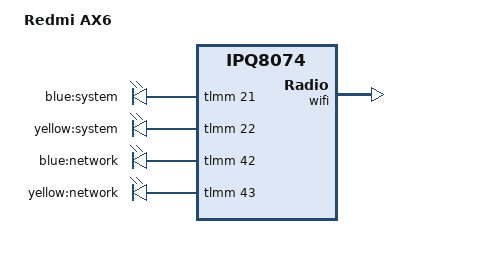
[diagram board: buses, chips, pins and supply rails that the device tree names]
// SPDX-License-Identifier: GPL-2.0-or-later OR MIT

/dts-v1/;

#include "ipq8071-xiaomi.dtsi"

/ {
	model = "Redmi AX6";
	compatible = "redmi,ax6", "qcom,ipq8074";

	leds {
		compatible = "gpio-leds";

		led_system_blue: system-blue {
			label = "blue:system";
			gpios = <&tlmm 21 GPIO_ACTIVE_HIGH>;
		};

		led_system_yellow: system-yellow {
			label = "yellow:system";
			gpios = <&tlmm 22 GPIO_ACTIVE_HIGH>;
		};

		network-blue {
			label = "blue:network";
			gpios = <&tlmm 42 GPIO_ACTIVE_HIGH>;
		};

		network-yellow {
			label = "yellow:network";
			gpios = <&tlmm 43 GPIO_ACTIVE_HIGH>;
		};
	};
};

/* AX6 can both have NAND of 256MiB or 128MiB.
 * To be on the safe side, assume 128MiB of NAND.
 */
&rootfs {
	reg = <0x02dc0000 0x05220000>;
};

&wifi {
	status = "okay";
	qcom,ath11k-fw-memory-mode = <1>;
	qcom,ath11k-calibration-variant = "Redmi-AX6";
};
